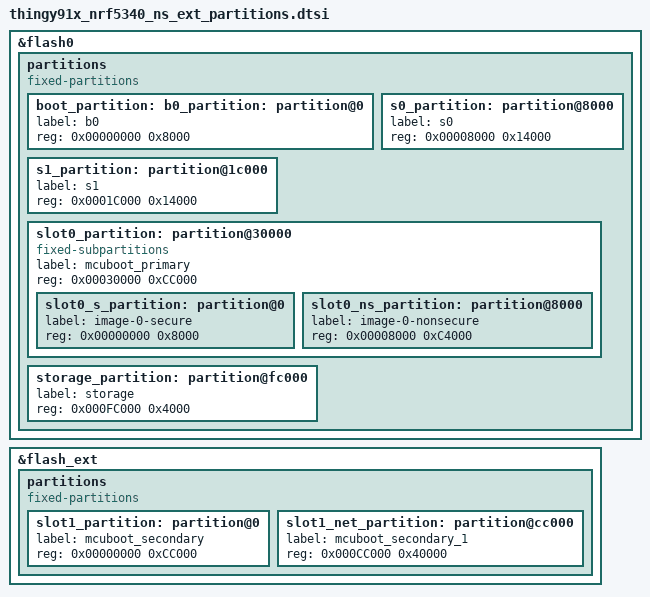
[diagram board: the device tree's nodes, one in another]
/*
 * Copyright (c) 2024 Nordic Semiconductor
 * SPDX-License-Identifier: LicenseRef-Nordic-5-Clause
 *
 * DTS-based partition layout for Thingy:91 X nRF5340 (TF-M + External Flash)
 * Converted from thingy91x_nrf5340_pm_static_ext_flash.yml
 */

/* Internal Flash Partitions */
&flash0 {
	partitions {
		compatible = "fixed-partitions";
		#address-cells = <1>;
		#size-cells = <1>;

		/* B0 - Immutable bootloader (32KB) */
		boot_partition: b0_partition: partition@0 {
			label = "b0";
			reg = <0x00000000 0x8000>;
		};

		/* S0 - MCUboot slot 0 (80KB) */
		s0_partition: partition@8000 {
			label = "s0";
			reg = <0x00008000 0x14000>;
		};

		/* S1 - MCUboot slot 1 (80KB) */
		s1_partition: partition@1c000 {
			label = "s1";
			reg = <0x0001C000 0x14000>;
		};

		/* Primary application area (816KB) */
		slot0_partition: partition@30000 {
			compatible = "fixed-subpartitions";
			label = "mcuboot_primary";
			reg = <0x00030000 0xCC000>;
			ranges = <0x0 0x30000 0xCC000>;
			#address-cells = <1>;
			#size-cells = <1>;

			/* TF-M secure partition (32KB) */
			slot0_s_partition: partition@0 {
				label = "image-0-secure";
				reg = <0x00000000 0x8000>;
			};

			/* Non-secure application partition (784KB) */
			slot0_ns_partition: partition@8000 {
				label = "image-0-nonsecure";
				reg = <0x00008000 0xC4000>;
			};
		};

		/* Settings storage (16KB) */
		storage_partition: partition@fc000 {
			label = "storage";
			reg = <0x000FC000 0x4000>;
		};
	};
};

/* External Flash Partitions */
&flash_ext {
	partitions {
		compatible = "fixed-partitions";
		#address-cells = <1>;
		#size-cells = <1>;

		/* Secondary application area (816KB - matches primary) */
		slot1_partition: partition@0 {
			label = "mcuboot_secondary";
			reg = <0x00000000 0xCC000>;
		};

		/* Network core secondary area (256KB) */
		slot1_net_partition: partition@cc000 {
			label = "mcuboot_secondary_1";
			reg = <0x000CC000 0x40000>;
		};
	};
};
